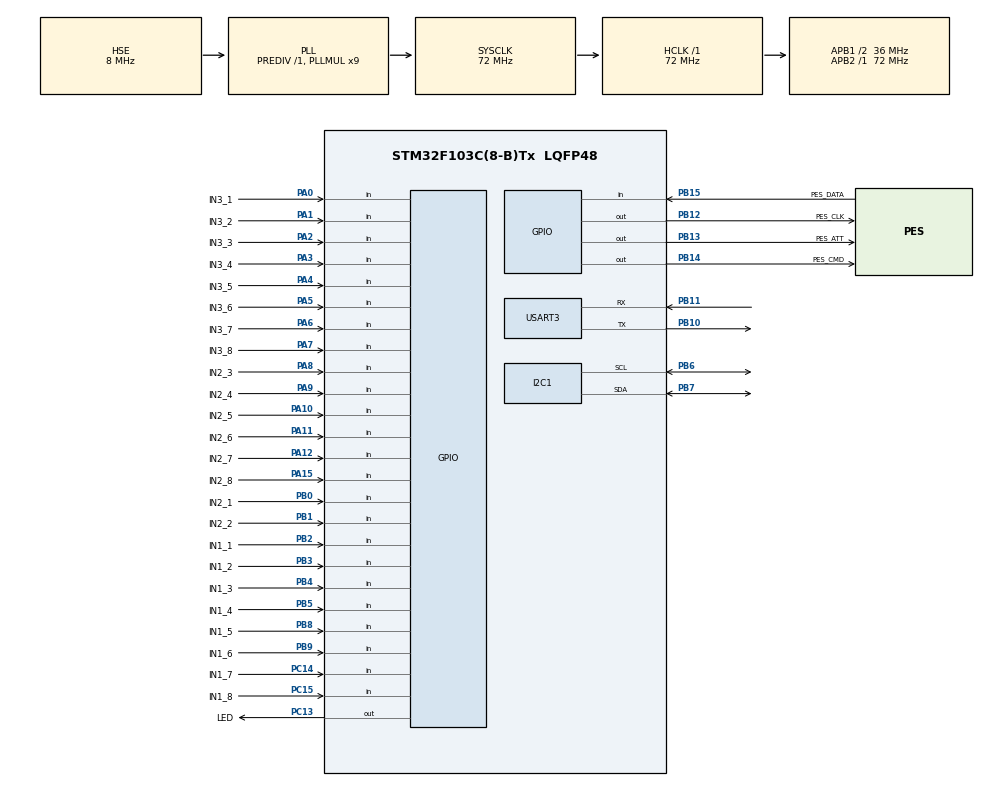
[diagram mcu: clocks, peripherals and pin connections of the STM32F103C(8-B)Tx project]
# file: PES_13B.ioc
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Mcu.Family=STM32F1
Mcu.Name=STM32F103C(8-B)Tx
Mcu.Package=LQFP48
NVIC.PriorityGroup=NVIC_PRIORITYGROUP_4
NVIC.USART3_IRQn=true\:0\:0\:false\:false\:true\:true\:true\:true
PA0-WKUP.GPIO_Label=IN3_1
PA0-WKUP.GPIO_PuPd=GPIO_PULLUP
PA0-WKUP.Signal=GPIO_Input
PA1.GPIO_Label=IN3_2
PA1.GPIO_PuPd=GPIO_PULLUP
PA1.Signal=GPIO_Input
PA10.GPIO_Label=IN2_5
PA10.GPIO_PuPd=GPIO_PULLUP
PA10.Signal=GPIO_Input
PA11.GPIO_Label=IN2_6
PA11.GPIO_PuPd=GPIO_PULLUP
PA11.Signal=GPIO_Input
PA12.GPIO_Label=IN2_7
PA12.GPIO_PuPd=GPIO_PULLUP
PA12.Signal=GPIO_Input
PA13.Mode=Serial_Wire
PA13.Signal=SYS_JTMS-SWDIO
PA14.Mode=Serial_Wire
PA14.Signal=SYS_JTCK-SWCLK
PA15.GPIO_Label=IN2_8
PA15.GPIO_PuPd=GPIO_PULLUP
PA15.Signal=GPIO_Input
PA2.GPIO_Label=IN3_3
PA2.GPIO_PuPd=GPIO_PULLUP
PA2.Signal=GPIO_Input
PA3.GPIO_Label=IN3_4
PA3.GPIO_PuPd=GPIO_PULLUP
PA3.Signal=GPIO_Input
PA4.GPIO_Label=IN3_5
PA4.GPIO_PuPd=GPIO_PULLUP
PA4.Signal=GPIO_Input
PA5.GPIO_Label=IN3_6
PA5.GPIO_PuPd=GPIO_PULLUP
PA5.Signal=GPIO_Input
PA6.GPIO_Label=IN3_7
PA6.GPIO_PuPd=GPIO_PULLUP
PA6.Signal=GPIO_Input
PA7.GPIO_Label=IN3_8
PA7.GPIO_PuPd=GPIO_PULLUP
PA7.Signal=GPIO_Input
PA8.GPIO_Label=IN2_3
PA8.GPIO_PuPd=GPIO_PULLUP
PA8.Signal=GPIO_Input
PA9.GPIO_Label=IN2_4
PA9.GPIO_PuPd=GPIO_PULLUP
PA9.Signal=GPIO_Input
PB0.GPIO_Label=IN2_1
PB0.GPIO_PuPd=GPIO_PULLUP
PB0.Signal=GPIO_Input
PB1.GPIO_Label=IN2_2
PB1.GPIO_PuPd=GPIO_PULLUP
PB1.Signal=GPIO_Input
PB10.Mode=Asynchronous
PB10.Signal=USART3_TX
PB11.Mode=Asynchronous
PB11.Signal=USART3_RX
PB12.GPIO_Label=PES_CLK
PB12.Signal=GPIO_Output
PB13.GPIO_Label=PES_ATT
PB13.Signal=GPIO_Output
PB14.GPIO_Label=PES_CMD
PB14.Signal=GPIO_Output
PB15.GPIO_Label=PES_DATA
PB15.GPIO_PuPd=GPIO_PULLUP
PB15.Signal=GPIO_Input
PB2.GPIO_Label=IN1_1
PB2.GPIO_PuPd=GPIO_PULLUP
PB2.Signal=GPIO_Input
PB3.GPIO_Label=IN1_2
PB3.GPIO_PuPd=GPIO_PULLUP
PB3.Signal=GPIO_Input
PB4.GPIO_Label=IN1_3
PB4.GPIO_PuPd=GPIO_PULLUP
PB4.Signal=GPIO_Input
PB5.GPIO_Label=IN1_4
PB5.GPIO_PuPd=GPIO_PULLUP
PB5.Signal=GPIO_Input
PB6.Mode=I2C
PB6.Signal=I2C1_SCL
PB7.Mode=I2C
PB7.Signal=I2C1_SDA
PB8.GPIO_Label=IN1_5
PB8.GPIO_PuPd=GPIO_PULLUP
PB8.Signal=GPIO_Input
PB9.GPIO_Label=IN1_6
PB9.GPIO_PuPd=GPIO_PULLUP
PB9.Signal=GPIO_Input
PC13-TAMPER-RTC.GPIO_Label=LED
PC13-TAMPER-RTC.Signal=GPIO_Output
PC14-OSC32_IN.GPIO_Label=IN1_7
PC14-OSC32_IN.GPIO_PuPd=GPIO_PULLUP
PC14-OSC32_IN.Signal=GPIO_Input
PC15-OSC32_OUT.GPIO_Label=IN1_8
PC15-OSC32_OUT.GPIO_PuPd=GPIO_PULLUP
PC15-OSC32_OUT.Signal=GPIO_Input
PD0-OSC_IN.Mode=HSE-External-Oscillator
PD0-OSC_IN.Signal=RCC_OSC_IN
PD1-OSC_OUT.Mode=HSE-External-Oscillator
PD1-OSC_OUT.Signal=RCC_OSC_OUT
ProjectManager.HeapSize=0x200
ProjectManager.StackSize=0x400
ProjectManager.TargetToolchain=MDK-ARM V5.32
RCC.AHBFreq_Value=72000000
RCC.APB1CLKDivider=RCC_HCLK_DIV2
RCC.APB1Freq_Value=36000000
RCC.APB1TimFreq_Value=72000000
RCC.APB2Freq_Value=72000000
RCC.APB2TimFreq_Value=72000000
RCC.HCLKFreq_Value=72000000
RCC.PLLMUL=RCC_PLL_MUL9
RCC.PLLSourceVirtual=RCC_PLLSOURCE_HSE
RCC.SYSCLKFreq_VALUE=72000000
RCC.SYSCLKSource=RCC_SYSCLKSOURCE_PLLCLK
RCC.USBFreq_Value=72000000
USART3.VirtualMode=VM_ASYNC
board=custom

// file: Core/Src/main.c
/* USER CODE BEGIN Header */
/**
  ******************************************************************************
  * @file           : main.c
  * @brief          : Main program body
  ******************************************************************************
  * @attention
  *
  * Copyright (c) 2023 STMicroelectronics.
  * All rights reserved.
  *
  * This software is licensed under terms that can be found in the LICENSE file
  * in the root directory of this software component.
  * If no LICENSE file comes with this software, it is provided AS-IS.
  *
  ******************************************************************************
  */
/* USER CODE END Header */
#include "main.h"

/* USER CODE BEGIN Includes */
#include "main-app.h"
/* USER CODE END Includes */

I2C_HandleTypeDef hi2c1;

UART_HandleTypeDef huart3;

void SystemClock_Config(void);
static void MX_GPIO_Init(void);
static void MX_I2C1_Init(void);
static void MX_USART3_UART_Init(void);

int main(void)
{

  /* MCU Configuration--------------------------------------------------------*/

  /* Reset of all peripherals, Initializes the Flash interface and the Systick. */
  HAL_Init();

  /* Configure the system clock */
  SystemClock_Config();

  /* Initialize all configured peripherals */
  MX_GPIO_Init();
  MX_I2C1_Init();
  MX_USART3_UART_Init();
  /* USER CODE BEGIN 2 */
	main_Init();
  /* USER CODE END 2 */

  /* Infinite loop */
  while (1)
  {

    /* USER CODE BEGIN 3 */
		main_process();
  }
  /* USER CODE END 3 */
}

void SystemClock_Config(void)
{
  RCC_OscInitTypeDef RCC_OscInitStruct = {0};
  RCC_ClkInitTypeDef RCC_ClkInitStruct = {0};

  /** Initializes the RCC Oscillators according to the specified parameters
  * in the RCC_OscInitTypeDef structure.
  */
  RCC_OscInitStruct.OscillatorType = RCC_OSCILLATORTYPE_HSE;
  RCC_OscInitStruct.HSEState = RCC_HSE_ON;
  RCC_OscInitStruct.HSEPredivValue = RCC_HSE_PREDIV_DIV1;
  RCC_OscInitStruct.HSIState = RCC_HSI_ON;
  RCC_OscInitStruct.PLL.PLLState = RCC_PLL_ON;
  RCC_OscInitStruct.PLL.PLLSource = RCC_PLLSOURCE_HSE;
  RCC_OscInitStruct.PLL.PLLMUL = RCC_PLL_MUL9;
  if (HAL_RCC_OscConfig(&RCC_OscInitStruct) != HAL_OK)
  {
    Error_Handler();
  }

  /** Initializes the CPU, AHB and APB buses clocks
  */
  RCC_ClkInitStruct.ClockType = RCC_CLOCKTYPE_HCLK|RCC_CLOCKTYPE_SYSCLK
                              |RCC_CLOCKTYPE_PCLK1|RCC_CLOCKTYPE_PCLK2;
  RCC_ClkInitStruct.SYSCLKSource = RCC_SYSCLKSOURCE_PLLCLK;
  RCC_ClkInitStruct.AHBCLKDivider = RCC_SYSCLK_DIV1;
  RCC_ClkInitStruct.APB1CLKDivider = RCC_HCLK_DIV2;
  RCC_ClkInitStruct.APB2CLKDivider = RCC_HCLK_DIV1;

  if (HAL_RCC_ClockConfig(&RCC_ClkInitStruct, FLASH_LATENCY_2) != HAL_OK)
  {
    Error_Handler();
  }
}

static void MX_I2C1_Init(void)
{

  hi2c1.Instance = I2C1;
  hi2c1.Init.ClockSpeed = 100000;
  hi2c1.Init.DutyCycle = I2C_DUTYCYCLE_2;
  hi2c1.Init.OwnAddress1 = 0;
  hi2c1.Init.AddressingMode = I2C_ADDRESSINGMODE_7BIT;
  hi2c1.Init.DualAddressMode = I2C_DUALADDRESS_DISABLE;
  hi2c1.Init.OwnAddress2 = 0;
  hi2c1.Init.GeneralCallMode = I2C_GENERALCALL_DISABLE;
  hi2c1.Init.NoStretchMode = I2C_NOSTRETCH_DISABLE;
  if (HAL_I2C_Init(&hi2c1) != HAL_OK)
  {
    Error_Handler();
  }

}

static void MX_USART3_UART_Init(void)
{

  huart3.Instance = USART3;
  huart3.Init.BaudRate = 115200;
  huart3.Init.WordLength = UART_WORDLENGTH_8B;
  huart3.Init.StopBits = UART_STOPBITS_1;
  huart3.Init.Parity = UART_PARITY_NONE;
  huart3.Init.Mode = UART_MODE_TX_RX;
  huart3.Init.HwFlowCtl = UART_HWCONTROL_NONE;
  huart3.Init.OverSampling = UART_OVERSAMPLING_16;
  if (HAL_UART_Init(&huart3) != HAL_OK)
  {
    Error_Handler();
  }

}

static void MX_GPIO_Init(void)
{
  GPIO_InitTypeDef GPIO_InitStruct = {0};

  /* GPIO Ports Clock Enable */
  __HAL_RCC_GPIOC_CLK_ENABLE();
  __HAL_RCC_GPIOD_CLK_ENABLE();
  __HAL_RCC_GPIOA_CLK_ENABLE();
  __HAL_RCC_GPIOB_CLK_ENABLE();

  /*Configure GPIO pin Output Level */
  HAL_GPIO_WritePin(LED_GPIO_Port, LED_Pin, GPIO_PIN_RESET);

  /*Configure GPIO pin Output Level */
  HAL_GPIO_WritePin(GPIOB, PES_CLK_Pin|PES_ATT_Pin|PES_CMD_Pin, GPIO_PIN_RESET);

  /*Configure GPIO pin : LED_Pin */
  GPIO_InitStruct.Pin = LED_Pin;
  GPIO_InitStruct.Mode = GPIO_MODE_OUTPUT_PP;
  GPIO_InitStruct.Pull = GPIO_NOPULL;
  GPIO_InitStruct.Speed = GPIO_SPEED_FREQ_LOW;
  HAL_GPIO_Init(LED_GPIO_Port, &GPIO_InitStruct);

  /*Configure GPIO pins : IN1_7_Pin IN1_8_Pin */
  GPIO_InitStruct.Pin = IN1_7_Pin|IN1_8_Pin;
  GPIO_InitStruct.Mode = GPIO_MODE_INPUT;
  GPIO_InitStruct.Pull = GPIO_PULLUP;
  HAL_GPIO_Init(GPIOC, &GPIO_InitStruct);

  /*Configure GPIO pins : IN3_1_Pin IN3_2_Pin IN3_3_Pin IN3_4_Pin
                           IN3_5_Pin IN3_6_Pin IN3_7_Pin IN3_8_Pin
                           IN2_3_Pin IN2_4_Pin IN2_5_Pin IN2_6_Pin
                           IN2_7_Pin IN2_8_Pin */
  GPIO_InitStruct.Pin = IN3_1_Pin|IN3_2_Pin|IN3_3_Pin|IN3_4_Pin
                          |IN3_5_Pin|IN3_6_Pin|IN3_7_Pin|IN3_8_Pin
                          |IN2_3_Pin|IN2_4_Pin|IN2_5_Pin|IN2_6_Pin
                          |IN2_7_Pin|IN2_8_Pin;
  GPIO_InitStruct.Mode = GPIO_MODE_INPUT;
  GPIO_InitStruct.Pull = GPIO_PULLUP;
  HAL_GPIO_Init(GPIOA, &GPIO_InitStruct);

  /*Configure GPIO pins : IN2_1_Pin IN2_2_Pin IN1_1_Pin PES_DATA_Pin
                           IN1_2_Pin IN1_3_Pin IN1_4_Pin IN1_5_Pin
                           IN1_6_Pin */
  GPIO_InitStruct.Pin = IN2_1_Pin|IN2_2_Pin|IN1_1_Pin|PES_DATA_Pin
                          |IN1_2_Pin|IN1_3_Pin|IN1_4_Pin|IN1_5_Pin
                          |IN1_6_Pin;
  GPIO_InitStruct.Mode = GPIO_MODE_INPUT;
  GPIO_InitStruct.Pull = GPIO_PULLUP;
  HAL_GPIO_Init(GPIOB, &GPIO_InitStruct);

  /*Configure GPIO pins : PES_CLK_Pin PES_ATT_Pin PES_CMD_Pin */
  GPIO_InitStruct.Pin = PES_CLK_Pin|PES_ATT_Pin|PES_CMD_Pin;
  GPIO_InitStruct.Mode = GPIO_MODE_OUTPUT_PP;
  GPIO_InitStruct.Pull = GPIO_NOPULL;
  GPIO_InitStruct.Speed = GPIO_SPEED_FREQ_LOW;
  HAL_GPIO_Init(GPIOB, &GPIO_InitStruct);

}

void Error_Handler(void)
{
  __disable_irq();
  while (1)
  {
  }
}
